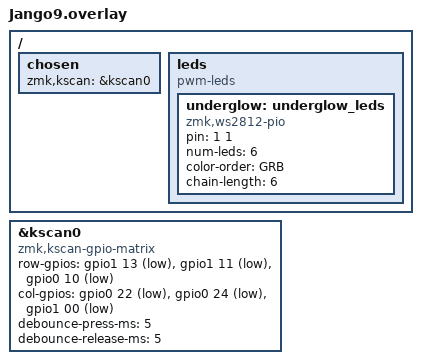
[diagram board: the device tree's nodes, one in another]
/ {
    chosen {
        zmk,kscan = &kscan0;
    };

    leds {
        compatible = "pwm-leds";

        underglow: underglow_leds {
            compatible = "zmk,ws2812-pio";
            pin = <1 1>;       // GPIO P1.01
            num-leds = <6>;    // You can change this depending on how many NeoPixels are connected
            color-order = "GRB";
            chain-length = <6>;
            status = "okay";
        };
    };
};

&kscan0 {
    compatible = "zmk,kscan-gpio-matrix";
    row-gpios = <&gpio1 13 (GPIO_PULL_UP | GPIO_ACTIVE_LOW)>,
                <&gpio1 11 (GPIO_PULL_UP | GPIO_ACTIVE_LOW)>,
                <&gpio0 10 (GPIO_PULL_UP | GPIO_ACTIVE_LOW)>;

    col-gpios = <&gpio0 22 GPIO_ACTIVE_LOW>,
                <&gpio0 24 GPIO_ACTIVE_LOW>,
                <&gpio1 00 GPIO_ACTIVE_LOW>;

    debounce-press-ms = <5>;
    debounce-release-ms = <5>;
};
